# PIC32MX350F256H device description
Architecture: MIPS; Family: PIC32MX; Series: PIC32MX
Registers are 32-bit, read-write, no defined reset value unless marked. A register's access mark holds for its fields unless they carry their own. Offsets are from the block's base; [hi:lo] are bit positions; {n}, {i} and the like mark numbered series; 'fields as' and 'values as' point back to an identical list.

## RPOR
Instances: RPOR 0x1f80fb40 in periph1
{0x0+4i} RPB{i}R (i=0..3) — Peripheral Pin Select Output Register
  [3:0] RPB{i}R
{0x0+4i} RPB{i}R (i=5..10) — Peripheral Pin Select Output Register
  [3:0] RPB{i}R
0x38 RPB14R — Peripheral Pin Select Output Register
  [3:0] RPB14R
0x3C RPB15R — Peripheral Pin Select Output Register
  [3:0] RPB15R
0x74 RPC13R — Peripheral Pin Select Output Register
  [3:0] RPC13R
0x78 RPC14R — Peripheral Pin Select Output Register
  [3:0] RPC14R
{0x80+4i} RPD{i}R (i=0..5) — Peripheral Pin Select Output Register
  [3:0] RPD{i}R
{0x80+4i} RPD{i}R (i=8..11) — Peripheral Pin Select Output Register
  [3:0] RPD{i}R
0xCC RPE3R — Peripheral Pin Select Output Register
  [3:0] RPE3R
0xD4 RPE5R — Peripheral Pin Select Output Register
  [3:0] RPE5R
{0x100+4i} RPF{i}R (i=0..6) — Peripheral Pin Select Output Register
  [3:0] RPF{i}R
{0x140+4i} RPG{i}R (i=6..9) — Peripheral Pin Select Output Register
  [3:0] RPG{i}R

## RTCC
Instances: RTCC 0x1f800200 in periph0
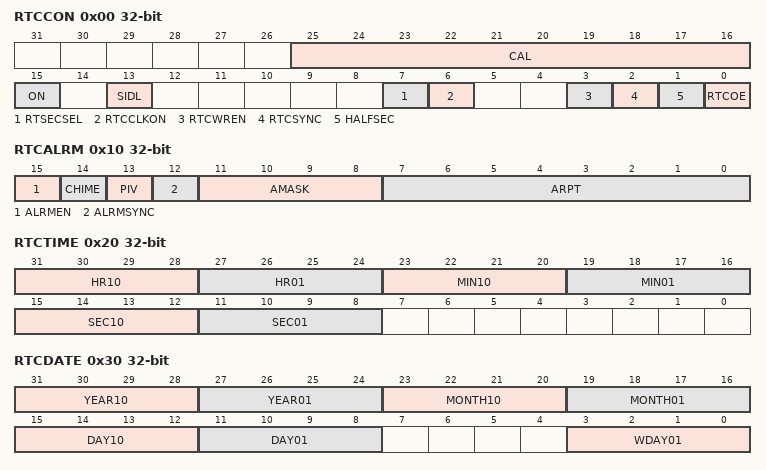
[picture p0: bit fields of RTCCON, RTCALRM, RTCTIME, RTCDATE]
0x00 RTCCON — RTC Control Register
  [25:16] CAL — RTC Drift Calibration bits
    0x1ff=Maximum positive adjustment; 1=Minimum positive adjustment; 0=No adjustment; 0x3ff=Minimum negative adjustment; 0x200=Maximum negative adjustment
  [15] ON — RTCC On bit
    1=RTCC module is enabled; 0=RTCC module is disabled
  [13] SIDL — Stop in Idle Mode bit
    1=Disables the PBCLK to the RTCC when CPU enters in Idle mode; 0=Continue normal operation in Idle mode
  [7] RTSECSEL — RTCC Seconds Clock Output Select bit
    1=RTCC Seconds Clock is selected for the RTCC pin; 0=RTCC Alarm Pulse is selected for the RTCC pin
  [6] RTCCLKON — RTCC Clock Enable Status bit
    1=RTCC Clock is actively running; 0=RTCC Clock is not running
  [3] RTCWREN — RTC Value Registers Write Enable bit
    1=RTC Value registers can be written to by the user; 0=RTC Value registers are locked out from being written to by the user
  [2] RTCSYNC — RTCC Value Registers Read Synchronization bit
    1=RTC Value registers can change while reading due to a rollover ripple that results in an invalid data read; 0=RTC Value registers can be read without concern about a rollover ripple
  [1] HALFSEC — Half-Second Status bit
    1=Second half period of a second; 0=First half period of a second
  [0] RTCOE — RTCC Output Enable bit
    1=RTCC clock output is enabled clock presented onto an I/O; 0=RTCC clock output is disabled
0x10 RTCALRM — RTC ALARM Control Register
  [15] ALRMEN — Alarm Enable bit
    1=Alarm is enabled; 0=Alarm is disabled
  [14] CHIME — Chime Enable bit
    1=Chime is enabled ARPT(7:0) is allowed to rollover from 0x00 to 0xFF; 0=Chime is disabled ARPT(7:0) stops once it reaches 0x00
  [13] PIV — Alarm Pulse Initial Value bit
    1=(When ALRMEN = 0) Alarm pulse high / (When ALRMEN = 1) PIV is read-only and returns state of the alarm pulse; 0=(When ALRMEN = 0) Alarm pulse low / (When ALRMEN = 1) PIV is read-only and returns state of the alarm pulse
  [12] ALRMSYNC — Alarm Sync bit
    1=ARPT(7:0) and ALRMEN may change as a result of a half second rollover during a read; 0=ARPT(7:0) and ALRMEN can be read without concerns of rollover because the prescaler is > 32 RTC clocks away from a half-second rollover
  [11:8] AMASK — Alarm Mask Configuration bits
    0=Every half-second; 1=Every second; 2=Every 10 seconds; 3=Every minute; 4=Every 10 minutes; 5=Every hour; 6=Once a day; 7=Once a week; 8=Once a month; 9=Once a year (except when configured for February 29; {v}=Reserved; do not use (v=10..15)
  [7:0] ARPT — Alarm Repeat Counter Value bits
    {v}=Alarm will trigger {v+1} times (v=0..255)
0x20 RTCTIME — RTC Time Value Register
  [31:28] HR10, [27:24] HR01, [23:20] MIN10, [19:16] MIN01, [15:12] SEC10, [11:8] SEC01
0x30 RTCDATE — RTC Date Value Register
  [31:28] YEAR10, [27:24] YEAR01, [23:20] MONTH10, [19:16] MONTH01, [15:12] DAY10, [11:8] DAY01, [3:0] WDAY01
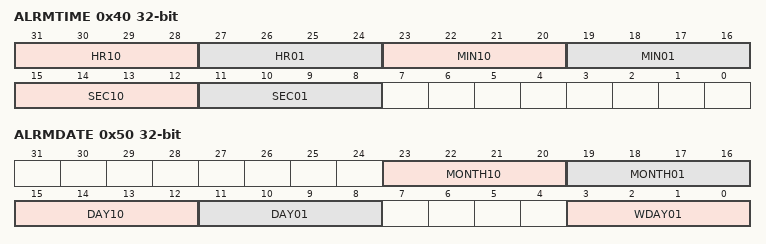
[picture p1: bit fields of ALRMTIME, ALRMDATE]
0x40 ALRMTIME — Alarm Time Value Register
  fields as RTCTIME
0x50 ALRMDATE — Alarm Date Value Register
  [23:20] MONTH10, [19:16] MONTH01, [15:12] DAY10, [11:8] DAY01, [3:0] WDAY01

## Notices in the file
Copyright (c) 2019 Microchip Technology Inc.
SPDX-License-Identifier: Apache-2.0
Licensed under the Apache License, Version 2.0 (the "License");
you may not use this file except in compliance with the License.
You may obtain a copy of the License at
http://www.apache.org/licenses/LICENSE-2.0
Unless required by applicable law or agreed to in writing, software
distributed under the License is distributed on an "AS IS" BASIS,
WITHOUT WARRANTIES OR CONDITIONS OF ANY KIND, either express or implied.
See the License for the specific language governing permissions and
limitations under the License.
